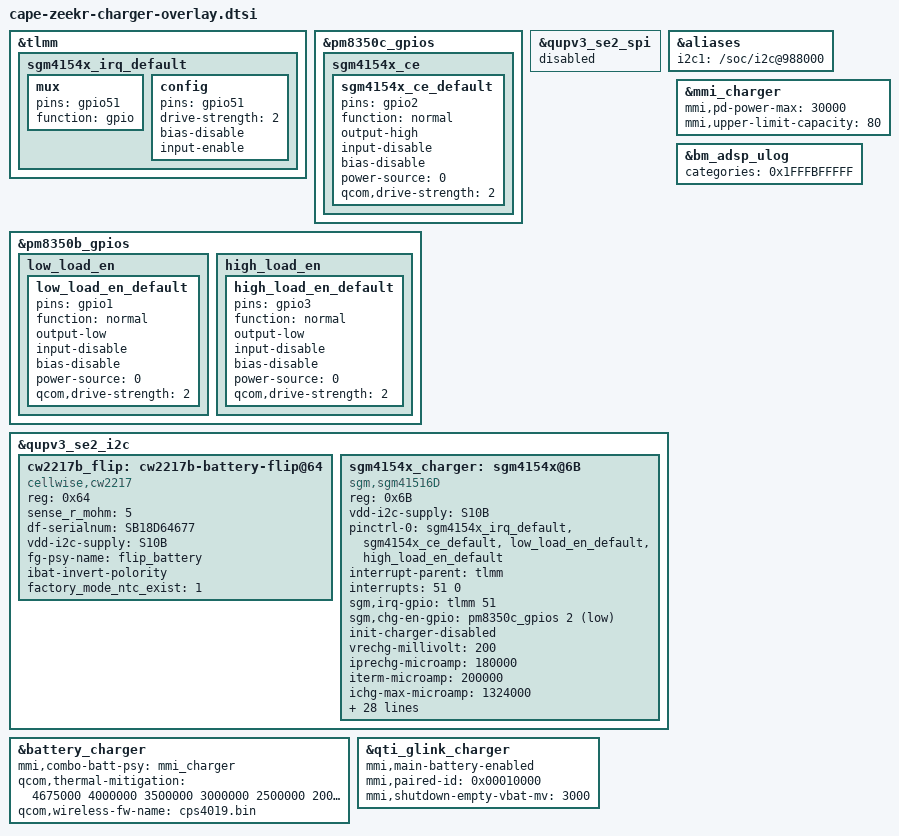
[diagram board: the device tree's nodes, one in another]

&tlmm {
	sgm4154x_irq_default: sgm4154x_irq_default {
		mux {
			pins = "gpio51";
			function = "gpio";
		};

		config {
			pins = "gpio51";
			drive-strength = <2>;
			bias-disable;
			input-enable;
		};
	};
};

&pm8350c_gpios {
	sgm4154x_ce {
		sgm4154x_ce_default: sgm4154x_ce_default {
			pins = "gpio2";
			function = "normal";
			output-high;
                        input-disable;
                        bias-disable;
                        power-source = <0>;       /* GPIO_LV, can be only 0: 1.8V */
                        qcom,drive-strength = <2>;
		};
	};
};

&pm8350b_gpios {
	low_load_en {
		low_load_en_default: low_load_en_default {
			pins = "gpio1";
			function = "normal";
			output-low;
                        input-disable;
                        bias-disable;
                        power-source = <0>;       /* GPIO_MV, 0: vph_pwr, 1: 1.8V */
                        qcom,drive-strength = <2>;
		};
	};

	high_load_en {
		high_load_en_default: high_load_en_default {
			pins = "gpio3";
			function = "normal";
			output-low;
                        input-disable;
                        bias-disable;
                        power-source = <0>;       /* GPIO_MV, 0: vph_pwr, 1: 1.8V */
                        qcom,drive-strength = <2>;
		};
	};
};

&qupv3_se2_spi {
	status = "disabled";
};

&aliases {
	i2c1 = "/soc/i2c@988000";
};

&qupv3_se2_i2c {
	status = "ok";
	cw2217b_flip: cw2217b-battery-flip@64 {
		compatible = "cellwise,cw2217";
		reg = <0x64>;
		sense_r_mohm = <5>;
		df-serialnum = "SB18D64677";
		vdd-i2c-supply = <&S10B>;
		fg-psy-name = "flip_battery";
		ibat-invert-polority;
		factory_mode_ntc_exist = <1>;
		#include "bat_setting/CW_PM08-atl-790mah.dtsi"
	};

	sgm4154x_charger: sgm4154x@6B {
		compatible = "sgm,sgm41516D";
		reg = <0x6B>;

		vdd-i2c-supply = <&S10B>;
		pinctrl-names = "default";
		pinctrl-0 = <&sgm4154x_irq_default &sgm4154x_ce_default
			     &low_load_en_default &high_load_en_default>;

		interrupt-parent = <&tlmm>;
		interrupts = <51 0>;		//irq num base on hardware design
		sgm,irq-gpio = <&tlmm 51 0>;	//irq num base on hardware design
		sgm,chg-en-gpio = <&pm8350c_gpios 2 GPIO_ACTIVE_LOW>;	//gpio num base on hardware design

		init-charger-disabled;
		vrechg-millivolt = <200>;
		iprechg-microamp = <180000>;
		iterm-microamp = <200000>;
		ichg-max-microamp = <1324000>;
		vchg-max-microvolt = <4600000>;
		ichg-microamp = <700000>;
		vchg-microvolt = <4400000>;
		input-current-limit-microamp = <1324000>;
		wls-current-limit-microamp = <200000>;

		mmi,ext-usb-psy-name = "usb";
		mmi,ext-wls-psy-name = "wireless";
		mmi,fg-psy-name = "flip_battery";
		mmi,chrg-iterm-ma = <100>;
		mmi,fg-iterm-ma = <100>;
		mmi,max-fv-mv = <4500>;
		mmi,max-fcc-ma = <1324>;
		mmi,demo-fv-mv = <4000>;
		mmi,df-serialnum = "SB18D44720";
		mmi,mmi-temp-zones = <0 4200 162 0>,
					<10 4250 405 243>,
					<15 4250 810 567>,
					<45 4300 1324 1053>,
					<45 4350 1053 810>,
					<60 4200 810 0>;

		mmi,paired-id = <0x00000001>;
		mmi,paired-esr = <5>;
		mmi,batt-esr = <5>;
		// delta_ocv ichg map table
		mmi,paired-ichg-table = <60 1324
					 90 900
					 120 600
					 150 300>;
		mmi,paired-load-thres = <800 400>;
		mmi,low-load-en-gpio = <&pm8350b_gpios 1 GPIO_ACTIVE_HIGH>;	//gpio num base on hardware design
		mmi,high-load-en-gpio = <&pm8350b_gpios 3 GPIO_ACTIVE_HIGH>;	//gpio num base on hardware design
		mmi,thermal-mitigation = <1324000 1000000 800000 500000 300000>;
	};
};

&mmi_charger {
	mmi,pd-power-max = <30000>;
	mmi,upper-limit-capacity = <80>;
};

&battery_charger {
	mmi,combo-batt-psy = <&mmi_charger>;
	qcom,thermal-mitigation = <4675000 4000000 3500000 3000000 2500000 2000000 1000000 500000>;
	qcom,wireless-fw-name = "cps4019.bin";
};

&qti_glink_charger {
	mmi,main-battery-enabled;
	mmi,paired-id = <0x00010000>;
	mmi,shutdown-empty-vbat-mv = <3000>;
};

&bm_adsp_ulog {
	categories = /bits/ 64 <0x1FFFBFFFFF>;
};
